# AST1060 register map
File version: 1.0
CPU: CM4 r0p1, little endian, MPU, FPU, 4 interrupt priority bits, 256 interrupts
Registers are 32-bit, read-write, reset 0x0 unless marked. A register's access mark holds for its fields unless they carry their own. Offsets are from the block's base; [hi:lo] are bit positions.

## sgpiom
Base 0x7E780500
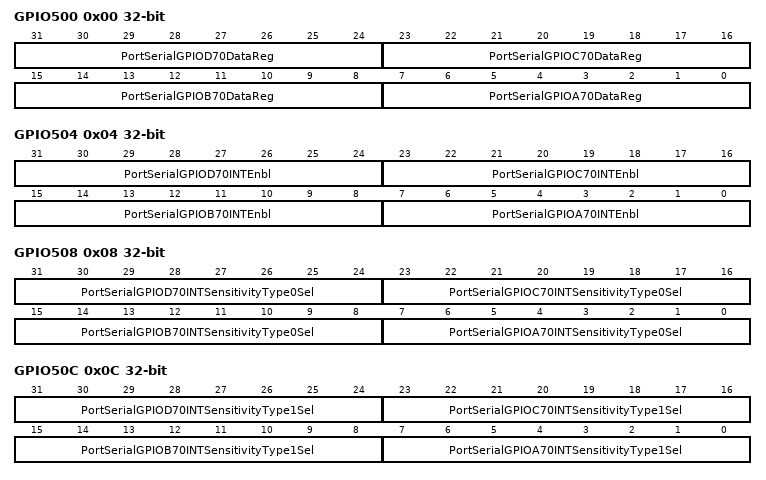
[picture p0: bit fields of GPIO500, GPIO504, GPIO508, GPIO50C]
0x00 GPIO500 — Serial GPIO\_A/B/C/D 1 Data Value Register
  [31:24] PortSerialGPIOD70DataReg — Port Serial GPIOD[7:0] data register
  [23:16] PortSerialGPIOC70DataReg — Port Serial GPIOC[7:0] data register
  [15:8] PortSerialGPIOB70DataReg — Port Serial GPIOB[7:0] data register
  [7:0] PortSerialGPIOA70DataReg — Port Serial GPIOA[7:0] data register
0x04 GPIO504 — Serial GPIO\_A/B/C/D 1 Interrupt Enable Register
  [31:24] PortSerialGPIOD70INTEnbl — Port Serial GPIOD[7:0] interrupt enable
  [23:16] PortSerialGPIOC70INTEnbl — Port Serial GPIOC[7:0] interrupt enable
  [15:8] PortSerialGPIOB70INTEnbl — Port Serial GPIOB[7:0] interrupt enable
  [7:0] PortSerialGPIOA70INTEnbl — Port Serial GPIOA[7:0] interrupt enable
0x08 GPIO508 — Serial GPIO\_A/B/C/D 1 Interrupt Sensitivity Type 0 Register
  [31:24] PortSerialGPIOD70INTSensitivityType0Sel — Port Serial GPIOD[7:0] interrupt sensitivity type 0 selection
  [23:16] PortSerialGPIOC70INTSensitivityType0Sel — Port Serial GPIOC[7:0] interrupt sensitivity type 0 selection
  [15:8] PortSerialGPIOB70INTSensitivityType0Sel — Port Serial GPIOB[7:0] interrupt sensitivity type 0 selection
  [7:0] PortSerialGPIOA70INTSensitivityType0Sel — Port Serial GPIOA[7:0] interrupt sensitivity type 0 selection
0x0C GPIO50C — Serial GPIO\_A/B/C/D 1 Interrupt Sensitivity Type 1 Register
  [31:24] PortSerialGPIOD70INTSensitivityType1Sel — Port Serial GPIOD[7:0] interrupt sensitivity type 1 selection
  [23:16] PortSerialGPIOC70INTSensitivityType1Sel — Port Serial GPIOC[7:0] interrupt sensitivity type 1 selection
  [15:8] PortSerialGPIOB70INTSensitivityType1Sel — Port Serial GPIOB[7:0] interrupt sensitivity type 1 selection
  [7:0] PortSerialGPIOA70INTSensitivityType1Sel — Port Serial GPIOA[7:0] interrupt sensitivity type 1 selection
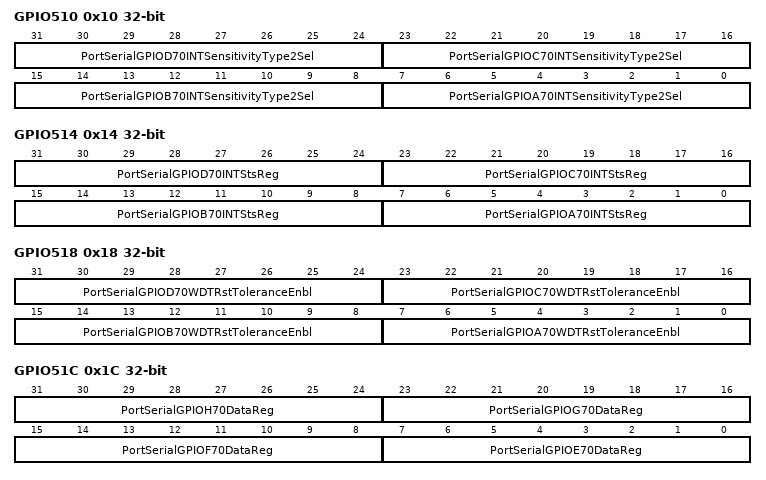
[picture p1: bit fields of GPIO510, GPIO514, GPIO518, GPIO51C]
0x10 GPIO510 — Serial GPIO\_A/B/C/D 1 Interrupt Sensitivity Type 2 Register
  [31:24] PortSerialGPIOD70INTSensitivityType2Sel — Port Serial GPIOD[7:0] interrupt sensitivity type 2 selection
  [23:16] PortSerialGPIOC70INTSensitivityType2Sel — Port Serial GPIOC[7:0] interrupt sensitivity type 2 selection
  [15:8] PortSerialGPIOB70INTSensitivityType2Sel — Port Serial GPIOB[7:0] interrupt sensitivity type 2 selection
  [7:0] PortSerialGPIOA70INTSensitivityType2Sel — Port Serial GPIOA[7:0] interrupt sensitivity type 2 selection
0x14 GPIO514 — Serial GPIO\_A/B/C/D 1 Interrupt Status Register
  [31:24] PortSerialGPIOD70INTStsReg — Port Serial GPIOD[7:0] interrupt status register
  [23:16] PortSerialGPIOC70INTStsReg — Port Serial GPIOC[7:0] interrupt status register
  [15:8] PortSerialGPIOB70INTStsReg — Port Serial GPIOB[7:0] interrupt status register
  [7:0] PortSerialGPIOA70INTStsReg — Port Serial GPIOA[7:0] interrupt status register
0x18 GPIO518 — Serial GPIO\_A/B/C/D 1 Reset Tolerant Register
  [31:24] PortSerialGPIOD70WDTRstToleranceEnbl — Port Serial GPIOD[7:0] WDT reset tolerance enable
  [23:16] PortSerialGPIOC70WDTRstToleranceEnbl — Port Serial GPIOC[7:0] WDT reset tolerance enable
  [15:8] PortSerialGPIOB70WDTRstToleranceEnbl — Port Serial GPIOB[7:0] WDT reset tolerance enable
  [7:0] PortSerialGPIOA70WDTRstToleranceEnbl — Port Serial GPIOA[7:0] WDT reset tolerance enable
0x1C GPIO51C — Serial GPIO\_E/F/G/H 1 Data Value Register
  [31:24] PortSerialGPIOH70DataReg — Port Serial GPIOH[7:0] data register
  [23:16] PortSerialGPIOG70DataReg — Port Serial GPIOG[7:0] data register
  [15:8] PortSerialGPIOF70DataReg — Port Serial GPIOF[7:0] data register
  [7:0] PortSerialGPIOE70DataReg — Port Serial GPIOE[7:0] data register
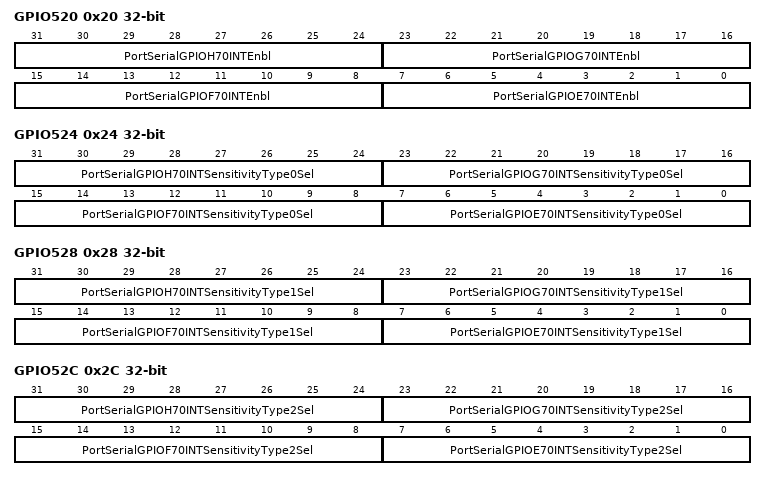
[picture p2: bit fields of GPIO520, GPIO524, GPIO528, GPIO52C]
0x20 GPIO520 — Serial GPIO\_E/F/G/H 1 Interrupt Enable Register
  [31:24] PortSerialGPIOH70INTEnbl — Port Serial GPIOH[7:0] interrupt enable
  [23:16] PortSerialGPIOG70INTEnbl — Port Serial GPIOG[7:0] interrupt enable
  [15:8] PortSerialGPIOF70INTEnbl — Port Serial GPIOF[7:0] interrupt enable
  [7:0] PortSerialGPIOE70INTEnbl — Port Serial GPIOE[7:0] interrupt enable
0x24 GPIO524 — Serial GPIO\_E/F/G/H 1 Interrupt Sensitivity Type 0 Register
  [31:24] PortSerialGPIOH70INTSensitivityType0Sel — Port Serial GPIOH[7:0] interrupt sensitivity type 0 selection
  [23:16] PortSerialGPIOG70INTSensitivityType0Sel — Port Serial GPIOG[7:0] interrupt sensitivity type 0 selection
  [15:8] PortSerialGPIOF70INTSensitivityType0Sel — Port Serial GPIOF[7:0] interrupt sensitivity type 0 selection
  [7:0] PortSerialGPIOE70INTSensitivityType0Sel — Port Serial GPIOE[7:0] interrupt sensitivity type 0 selection
0x28 GPIO528 — Serial GPIO\_E/F/G/H 1 Interrupt Sensitivity Type 1 Register
  [31:24] PortSerialGPIOH70INTSensitivityType1Sel — Port Serial GPIOH[7:0] interrupt sensitivity type 1 selection
  [23:16] PortSerialGPIOG70INTSensitivityType1Sel — Port Serial GPIOG[7:0] interrupt sensitivity type 1 selection
  [15:8] PortSerialGPIOF70INTSensitivityType1Sel — Port Serial GPIOF[7:0] interrupt sensitivity type 1 selection
  [7:0] PortSerialGPIOE70INTSensitivityType1Sel — Port Serial GPIOE[7:0] interrupt sensitivity type 1 selection
0x2C GPIO52C — Serial GPIO\_E/F/G/H 1 Interrupt Sensitivity Type 2 Register
  [31:24] PortSerialGPIOH70INTSensitivityType2Sel — Port Serial GPIOH[7:0] interrupt sensitivity type 2 selection
  [23:16] PortSerialGPIOG70INTSensitivityType2Sel — Port Serial GPIOG[7:0] interrupt sensitivity type 2 selection
  [15:8] PortSerialGPIOF70INTSensitivityType2Sel — Port Serial GPIOF[7:0] interrupt sensitivity type 2 selection
  [7:0] PortSerialGPIOE70INTSensitivityType2Sel — Port Serial GPIOE[7:0] interrupt sensitivity type 2 selection
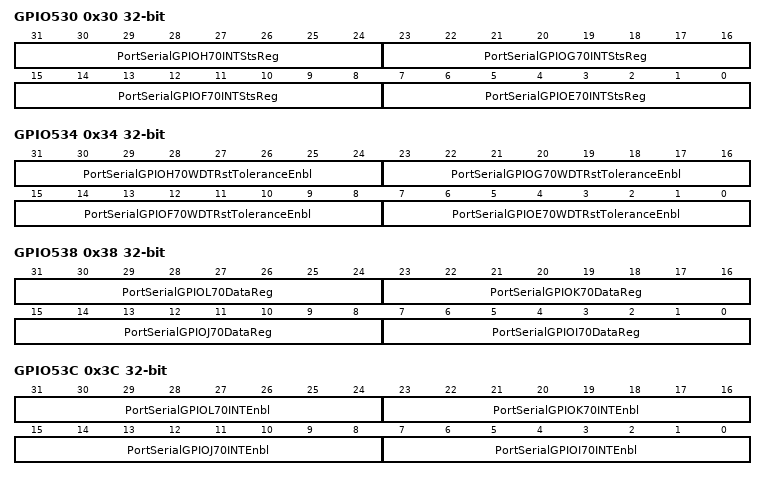
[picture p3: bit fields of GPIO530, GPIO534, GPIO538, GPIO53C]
0x30 GPIO530 — Serial GPIO\_E/F/G/H 1 Interrupt Status Register
  [31:24] PortSerialGPIOH70INTStsReg — Port Serial GPIOH[7:0] interrupt status register
  [23:16] PortSerialGPIOG70INTStsReg — Port Serial GPIOG[7:0] interrupt status register
  [15:8] PortSerialGPIOF70INTStsReg — Port Serial GPIOF[7:0] interrupt status register
  [7:0] PortSerialGPIOE70INTStsReg — Port Serial GPIOE[7:0] interrupt status register
0x34 GPIO534 — Serial GPIO\_E/F/G/H 1 Reset Tolerant Register
  [31:24] PortSerialGPIOH70WDTRstToleranceEnbl — Port Serial GPIOH[7:0] WDT reset tolerance enable
  [23:16] PortSerialGPIOG70WDTRstToleranceEnbl — Port Serial GPIOG[7:0] WDT reset tolerance enable
  [15:8] PortSerialGPIOF70WDTRstToleranceEnbl — Port Serial GPIOF[7:0] WDT reset tolerance enable
  [7:0] PortSerialGPIOE70WDTRstToleranceEnbl — Port Serial GPIOE[7:0] WDT reset tolerance enable
0x38 GPIO538 — Serial GPIO\_I/J/K/L 1 Data Value Register
  [31:24] PortSerialGPIOL70DataReg — Port Serial GPIOL[7:0] data register
  [23:16] PortSerialGPIOK70DataReg — Port Serial GPIOK[7:0] data register
  [15:8] PortSerialGPIOJ70DataReg — Port Serial GPIOJ[7:0] data register
  [7:0] PortSerialGPIOI70DataReg — Port Serial GPIOI[7:0] data register
0x3C GPIO53C — Serial GPIO\_I/J/K/L 1 Interrupt Enable Register
  [31:24] PortSerialGPIOL70INTEnbl — Port Serial GPIOL[7:0] interrupt enable
  [23:16] PortSerialGPIOK70INTEnbl — Port Serial GPIOK[7:0] interrupt enable
  [15:8] PortSerialGPIOJ70INTEnbl — Port Serial GPIOJ[7:0] interrupt enable
  [7:0] PortSerialGPIOI70INTEnbl — Port Serial GPIOI[7:0] interrupt enable
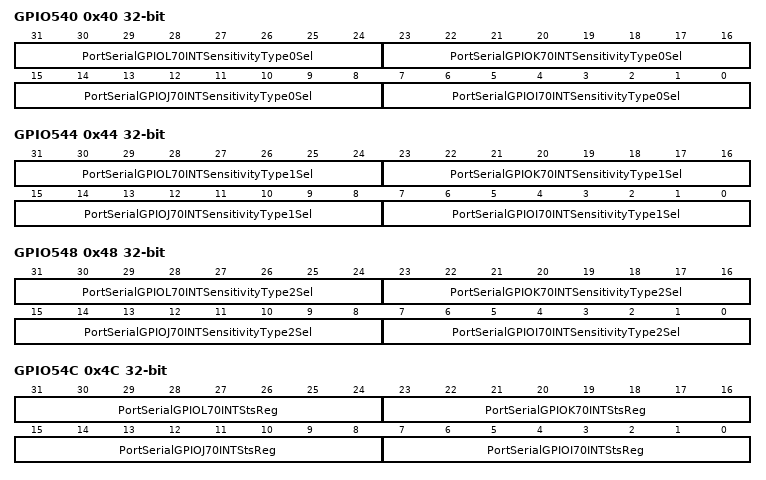
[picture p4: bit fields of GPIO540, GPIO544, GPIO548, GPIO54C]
0x40 GPIO540 — Serial GPIO\_I/J/K/L 1 Interrupt Sensitivity Type 0 Register
  [31:24] PortSerialGPIOL70INTSensitivityType0Sel — Port Serial GPIOL[7:0] interrupt sensitivity type 0 selection
  [23:16] PortSerialGPIOK70INTSensitivityType0Sel — Port Serial GPIOK[7:0] interrupt sensitivity type 0 selection
  [15:8] PortSerialGPIOJ70INTSensitivityType0Sel — Port Serial GPIOJ[7:0] interrupt sensitivity type 0 selection
  [7:0] PortSerialGPIOI70INTSensitivityType0Sel — Port Serial GPIOI[7:0] interrupt sensitivity type 0 selection
0x44 GPIO544 — Serial GPIO\_I/J/K/L 1 Interrupt Sensitivity Type 1 Register
  [31:24] PortSerialGPIOL70INTSensitivityType1Sel — Port Serial GPIOL[7:0] interrupt sensitivity type 1 selection
  [23:16] PortSerialGPIOK70INTSensitivityType1Sel — Port Serial GPIOK[7:0] interrupt sensitivity type 1 selection
  [15:8] PortSerialGPIOJ70INTSensitivityType1Sel — Port Serial GPIOJ[7:0] interrupt sensitivity type 1 selection
  [7:0] PortSerialGPIOI70INTSensitivityType1Sel — Port Serial GPIOI[7:0] interrupt sensitivity type 1 selection
0x48 GPIO548 — Serial GPIO\_I/J/K/L 1 Interrupt Sensitivity Type 2 Register
  [31:24] PortSerialGPIOL70INTSensitivityType2Sel — Port Serial GPIOL[7:0] interrupt sensitivity type 2 selection
  [23:16] PortSerialGPIOK70INTSensitivityType2Sel — Port Serial GPIOK[7:0] interrupt sensitivity type 2 selection
  [15:8] PortSerialGPIOJ70INTSensitivityType2Sel — Port Serial GPIOJ[7:0] interrupt sensitivity type 2 selection
  [7:0] PortSerialGPIOI70INTSensitivityType2Sel — Port Serial GPIOI[7:0] interrupt sensitivity type 2 selection
0x4C GPIO54C — Serial GPIO\_I/J/K/L 1 Interrupt Status Register
  [31:24] PortSerialGPIOL70INTStsReg — Port Serial GPIOL[7:0] interrupt status register
  [23:16] PortSerialGPIOK70INTStsReg — Port Serial GPIOK[7:0] interrupt status register
  [15:8] PortSerialGPIOJ70INTStsReg — Port Serial GPIOJ[7:0] interrupt status register
  [7:0] PortSerialGPIOI70INTStsReg — Port Serial GPIOI[7:0] interrupt status register
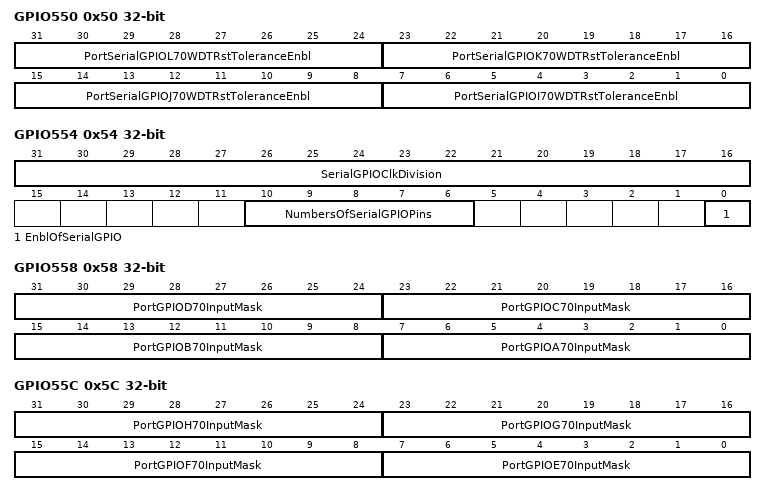
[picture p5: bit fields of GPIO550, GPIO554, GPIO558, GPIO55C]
0x50 GPIO550 — Serial GPIO\_I/J/K/L 1 Reset Tolerant Register
  [31:24] PortSerialGPIOL70WDTRstToleranceEnbl — Port Serial GPIOL[7:0] WDT reset tolerance enable
  [23:16] PortSerialGPIOK70WDTRstToleranceEnbl — Port Serial GPIOK[7:0] WDT reset tolerance enable
  [15:8] PortSerialGPIOJ70WDTRstToleranceEnbl — Port Serial GPIOJ[7:0] WDT reset tolerance enable
  [7:0] PortSerialGPIOI70WDTRstToleranceEnbl — Port Serial GPIOI[7:0] WDT reset tolerance enable
0x54 GPIO554 — Serial GPIO 1 Configuration Register
  [31:16] SerialGPIOClkDivision — Serial GPIO clock division
  [10:6] NumbersOfSerialGPIOPins
  [0] EnblOfSerialGPIO — Enable of Serial GPIO
0x58 GPIO558 — Serial GPIO\_A/B/C/D Input Mask Register
  [31:24] PortGPIOD70InputMask, [23:16] PortGPIOC70InputMask, [15:8] PortGPIOB70InputMask, [7:0] PortGPIOA70InputMask
0x5C GPIO55C — Serial GPIO\_E/F/G/H Input Mask Register
  [31:24] PortGPIOH70InputMask, [23:16] PortGPIOG70InputMask, [15:8] PortGPIOF70InputMask, [7:0] PortGPIOE70InputMask
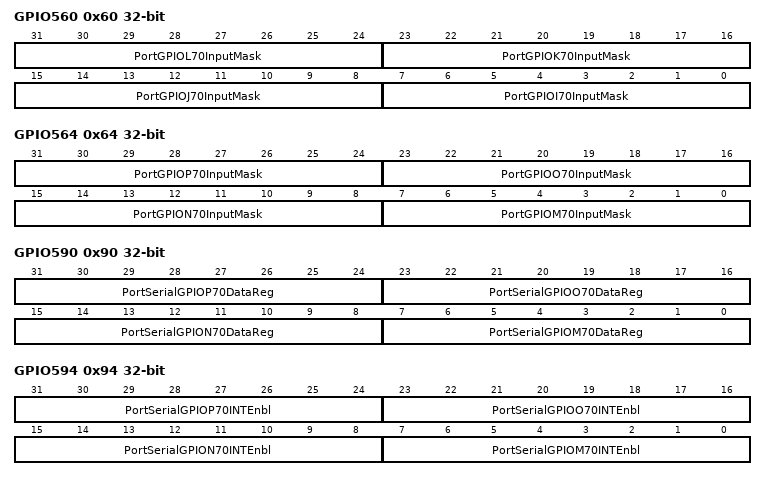
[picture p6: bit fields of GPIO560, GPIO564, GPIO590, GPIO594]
0x60 GPIO560 — Serial GPIO\_I/J/K/L Input Mask Register
  [31:24] PortGPIOL70InputMask, [23:16] PortGPIOK70InputMask, [15:8] PortGPIOJ70InputMask, [7:0] PortGPIOI70InputMask
0x64 GPIO564 — Serial GPIO\_M/N/O/P Input Mask Register
  [31:24] PortGPIOP70InputMask, [23:16] PortGPIOO70InputMask, [15:8] PortGPION70InputMask, [7:0] PortGPIOM70InputMask
0x70 GPIO570 — Serial GPIO\_A/B/C/D 1 Data Read Register
  [31:0] DataWrittenToGPIO500 ro
0x74 GPIO574 — Serial GPIO\_E/F/G/H 1 Data Read Register
  [31:0] DataWrittenToGPIO51C ro
0x78 GPIO578 — Serial GPIO\_I/J/K/L 1 Data Read Register
  [31:0] DataWrittenToGPIO538 ro
0x90 GPIO590 — Serial GPIO\_M/N/O/P 1 Data Value Register
  [31:24] PortSerialGPIOP70DataReg — Port Serial GPIOP[7:0] data register
  [23:16] PortSerialGPIOO70DataReg — Port Serial GPIOO[7:0] data register
  [15:8] PortSerialGPION70DataReg — Port Serial GPION[7:0] data register
  [7:0] PortSerialGPIOM70DataReg — Port Serial GPIOM[7:0] data register
0x94 GPIO594 — Serial GPIO\_M/N/O/P 1 Interrupt Enable Register
  [31:24] PortSerialGPIOP70INTEnbl — Port Serial GPIOP[7:0] interrupt enable
  [23:16] PortSerialGPIOO70INTEnbl — Port Serial GPIOO[7:0] interrupt enable
  [15:8] PortSerialGPION70INTEnbl — Port Serial GPION[7:0] interrupt enable
  [7:0] PortSerialGPIOM70INTEnbl — Port Serial GPIOM[7:0] interrupt enable
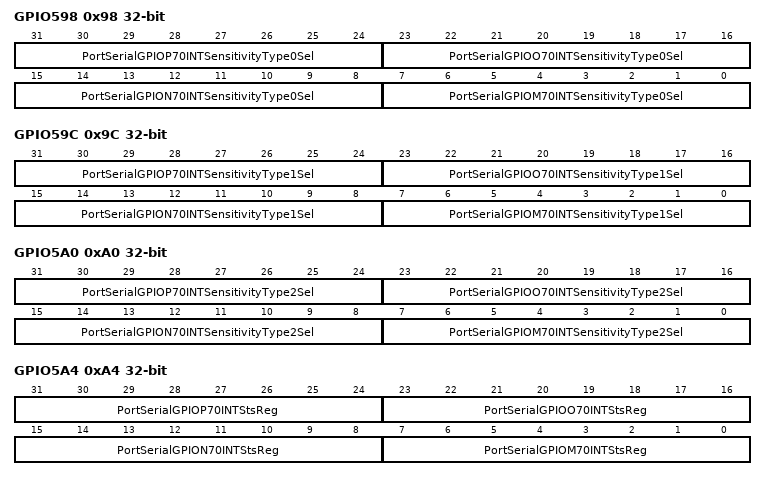
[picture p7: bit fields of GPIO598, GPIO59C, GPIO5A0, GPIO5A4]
0x98 GPIO598 — Serial GPIO\_M/N/O/P 1 Interrupt Sensitivity Type 0 Register
  [31:24] PortSerialGPIOP70INTSensitivityType0Sel — Port Serial GPIOP[7:0] interrupt sensitivity type 0 selection
  [23:16] PortSerialGPIOO70INTSensitivityType0Sel — Port Serial GPIOO[7:0] interrupt sensitivity type 0 selection
  [15:8] PortSerialGPION70INTSensitivityType0Sel — Port Serial GPION[7:0] interrupt sensitivity type 0 selection
  [7:0] PortSerialGPIOM70INTSensitivityType0Sel — Port Serial GPIOM[7:0] interrupt sensitivity type 0 selection
0x9C GPIO59C — Serial GPIO\_M/N/O/P 1 Interrupt Sensitivity Type 1 Register
  [31:24] PortSerialGPIOP70INTSensitivityType1Sel — Port Serial GPIOP[7:0] interrupt sensitivity type 1 selection
  [23:16] PortSerialGPIOO70INTSensitivityType1Sel — Port Serial GPIOO[7:0] interrupt sensitivity type 1 selection
  [15:8] PortSerialGPION70INTSensitivityType1Sel — Port Serial GPION[7:0] interrupt sensitivity type 1 selection
  [7:0] PortSerialGPIOM70INTSensitivityType1Sel — Port Serial GPIOM[7:0] interrupt sensitivity type 1 selection
0xA0 GPIO5A0 — Serial GPIO\_M/N/O/P 1 Interrupt Sensitivity Type 2 Register
  [31:24] PortSerialGPIOP70INTSensitivityType2Sel — Port Serial GPIOP[7:0] interrupt sensitivity type 2 selection
  [23:16] PortSerialGPIOO70INTSensitivityType2Sel — Port Serial GPIOO[7:0] interrupt sensitivity type 2 selection
  [15:8] PortSerialGPION70INTSensitivityType2Sel — Port Serial GPION[7:0] interrupt sensitivity type 2 selection
  [7:0] PortSerialGPIOM70INTSensitivityType2Sel — Port Serial GPIOM[7:0] interrupt sensitivity type 2 selection
0xA4 GPIO5A4 — Serial GPIO\_M/N/O/P 1 Interrupt Status Register
  [31:24] PortSerialGPIOP70INTStsReg — Port Serial GPIOP[7:0] interrupt status register
  [23:16] PortSerialGPIOO70INTStsReg — Port Serial GPIOO[7:0] interrupt status register
  [15:8] PortSerialGPION70INTStsReg — Port Serial GPION[7:0] interrupt status register
  [7:0] PortSerialGPIOM70INTStsReg — Port Serial GPIOM[7:0] interrupt status register
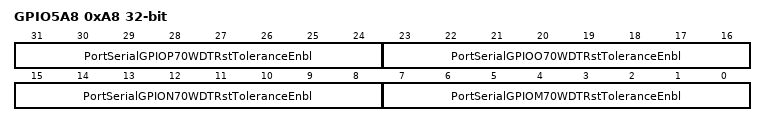
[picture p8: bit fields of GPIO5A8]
0xA8 GPIO5A8 — Serial GPIO\_M/N/O/P 1 Reset Tolerant Register
  [31:24] PortSerialGPIOP70WDTRstToleranceEnbl — Port Serial GPIOP[7:0] WDT reset tolerance enable
  [23:16] PortSerialGPIOO70WDTRstToleranceEnbl — Port Serial GPIOO[7:0] WDT reset tolerance enable
  [15:8] PortSerialGPION70WDTRstToleranceEnbl — Port Serial GPION[7:0] WDT reset tolerance enable
  [7:0] PortSerialGPIOM70WDTRstToleranceEnbl — Port Serial GPIOM[7:0] WDT reset tolerance enable
